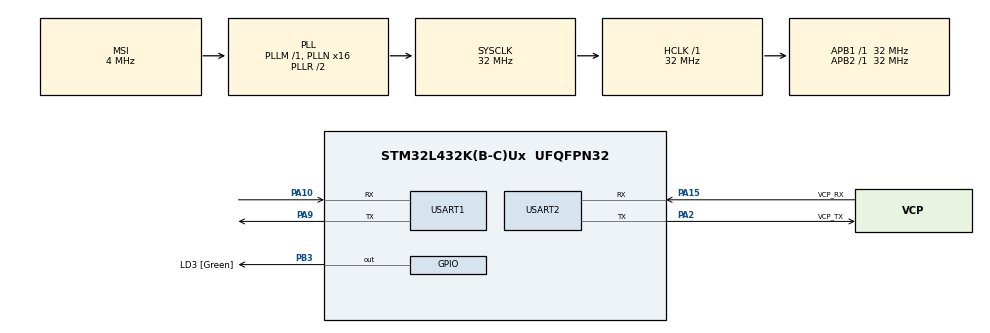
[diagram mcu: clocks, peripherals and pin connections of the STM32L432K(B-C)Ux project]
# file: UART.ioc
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Dma.Request0=USART1_RX
Dma.USART1_RX.0.Direction=DMA_PERIPH_TO_MEMORY
Dma.USART1_RX.0.Instance=DMA1_Channel5
Dma.USART1_RX.0.MemDataAlignment=DMA_MDATAALIGN_BYTE
Dma.USART1_RX.0.MemInc=DMA_MINC_ENABLE
Dma.USART1_RX.0.Mode=DMA_CIRCULAR
Dma.USART1_RX.0.PeriphDataAlignment=DMA_PDATAALIGN_BYTE
Dma.USART1_RX.0.PeriphInc=DMA_PINC_DISABLE
Dma.USART1_RX.0.Priority=DMA_PRIORITY_LOW
Mcu.Family=STM32L4
Mcu.Name=STM32L432K(B-C)Ux
Mcu.Package=UFQFPN32
NVIC.DMA1_Channel5_IRQn=true\:0\:0\:false\:false\:true\:false\:true
NVIC.PriorityGroup=NVIC_PRIORITYGROUP_4
NVIC.TIM6_DAC_IRQn=true\:0\:0\:false\:false\:true\:true\:true
NVIC.USART1_IRQn=true\:0\:0\:false\:false\:true\:true\:true
PA0.GPIO_Label=MCO [High speed clock in]
PA0.Mode=HSE-External-Clock-Source-for-LittleOrca
PA0.Signal=RCC_CK_IN
PA10.Mode=Asynchronous
PA10.Signal=USART1_RX
PA13\ (JTMS-SWDIO).GPIO_Label=SWDIO
PA13\ (JTMS-SWDIO).Mode=Serial_Wire
PA13\ (JTMS-SWDIO).Signal=SYS_JTMS-SWDIO
PA14\ (JTCK-SWCLK).GPIO_Label=SWCLK
PA14\ (JTCK-SWCLK).Mode=Serial_Wire
PA14\ (JTCK-SWCLK).Signal=SYS_JTCK-SWCLK
PA15\ (JTDI).GPIO_Label=VCP_RX
PA15\ (JTDI).Mode=Asynchronous
PA15\ (JTDI).Signal=USART2_RX
PA2.GPIO_Label=VCP_TX
PA2.Mode=Asynchronous
PA2.Signal=USART2_TX
PA9.Mode=Asynchronous
PA9.Signal=USART1_TX
PB3\ (JTDO-TRACESWO).GPIO_Label=LD3 [Green]
PB3\ (JTDO-TRACESWO).Signal=GPIO_Output
PC14-OSC32_IN\ (PC14).Mode=LSE-External-Oscillator
PC14-OSC32_IN\ (PC14).Signal=RCC_OSC32_IN
PC15-OSC32_OUT\ (PC15).Mode=LSE-External-Oscillator
PC15-OSC32_OUT\ (PC15).Signal=RCC_OSC32_OUT
ProjectManager.HeapSize=0x200
ProjectManager.StackSize=0x400
ProjectManager.TargetToolchain=STM32CubeIDE
RCC.AHBFreq_Value=32000000
RCC.APB1Freq_Value=32000000
RCC.APB1TimFreq_Value=32000000
RCC.APB2Freq_Value=32000000
RCC.APB2TimFreq_Value=32000000
RCC.CortexFreq_Value=32000000
RCC.HCLKFreq_Value=32000000
RCC.HSE_VALUE=8000000
RCC.HSI16_VALUE=16000000
RCC.HSI48_VALUE=48000000
RCC.HSI_VALUE=16000000
RCC.MSI_VALUE=4000000
RCC.PLLMUL=RCC_PLLMUL_4
RCC.PLLN=16
RCC.SYSCLKFreq_VALUE=32000000
RCC.SYSCLKSource=RCC_SYSCLKSOURCE_PLLCLK
RCC.VCOOutputFreq_Value=64000000
TIM6.Period=10000
TIM6.Prescaler=32
USART1.OverrunDisableParam=ADVFEATURE_OVERRUN_ENABLE
USART1.Parity=PARITY_NONE
USART1.VirtualMode-Asynchronous=VM_ASYNC
USART2.VirtualMode-Asynchronous=VM_ASYNC
VP_TIM6_VS_ClockSourceINT.Mode=Enable_Timer
board=NUCLEO-L432KC

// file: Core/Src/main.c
/* USER CODE BEGIN Header */
/**
  ******************************************************************************
  * @file           : main.c
  * @brief          : Main program body
  ******************************************************************************
  * @attention
  *
  * <h2><center>&copy; Copyright (c) 2020 STMicroelectronics.
  * All rights reserved.</center></h2>
  *
  * This software component is licensed by ST under BSD 3-Clause license,
  * the "License"; You may not use this file except in compliance with the
  * License. You may obtain a copy of the License at:
  *                        opensource.org/licenses/BSD-3-Clause
  *
  ******************************************************************************
  */
/* USER CODE END Header */
#include "main.h"

/* USER CODE BEGIN Includes */

#include <stdio.h>
#include <sys/_stdint.h>
#include <string.h>
#include <com.h>

/* USER CODE END Includes */

TIM_HandleTypeDef htim6;

UART_HandleTypeDef huart1;
UART_HandleTypeDef huart2;
DMA_HandleTypeDef hdma_usart1_rx;

/* USER CODE BEGIN PV */

//DMA buffer for UART
char RX_Buffer[16];

/* USER CODE END PV */

void SystemClock_Config(void);
static void MX_GPIO_Init(void);
static void MX_DMA_Init(void);
static void MX_USART2_UART_Init(void);
static void MX_USART1_UART_Init(void);
static void MX_TIM6_Init(void);

/* USER CODE BEGIN 0 */

//reroute printf to UART1
int _write(int file, char *ptr, int len)
{
	HAL_UART_Transmit(&huart1,  (uint8_t*) ptr, len, 10);
    return len;
}

/* USER CODE END 0 */

int main(void)
{

  /* MCU Configuration--------------------------------------------------------*/

  /* Reset of all peripherals, Initializes the Flash interface and the Systick. */
  HAL_Init();

  /* Configure the system clock */
  SystemClock_Config();

  /* Initialize all configured peripherals */
  MX_GPIO_Init();
  MX_DMA_Init();
  MX_USART2_UART_Init();
  MX_USART1_UART_Init();
  MX_TIM6_Init();
  /* USER CODE BEGIN 2 */

  HAL_TIM_Base_Start_IT(&htim6);

  /* USER CODE END 2 */

  /* Infinite loop */
  while (1)
  {

	  //everything is handled inside ISR

  }
}

void SystemClock_Config(void)
{
  RCC_OscInitTypeDef RCC_OscInitStruct = {0};
  RCC_ClkInitTypeDef RCC_ClkInitStruct = {0};
  RCC_PeriphCLKInitTypeDef PeriphClkInit = {0};

  /** Configure LSE Drive Capability
  */
  HAL_PWR_EnableBkUpAccess();
  __HAL_RCC_LSEDRIVE_CONFIG(RCC_LSEDRIVE_LOW);
  /** Initializes the RCC Oscillators according to the specified parameters
  * in the RCC_OscInitTypeDef structure.
  */
  RCC_OscInitStruct.OscillatorType = RCC_OSCILLATORTYPE_LSE|RCC_OSCILLATORTYPE_MSI;
  RCC_OscInitStruct.LSEState = RCC_LSE_ON;
  RCC_OscInitStruct.MSIState = RCC_MSI_ON;
  RCC_OscInitStruct.MSICalibrationValue = 0;
  RCC_OscInitStruct.MSIClockRange = RCC_MSIRANGE_6;
  RCC_OscInitStruct.PLL.PLLState = RCC_PLL_ON;
  RCC_OscInitStruct.PLL.PLLSource = RCC_PLLSOURCE_MSI;
  RCC_OscInitStruct.PLL.PLLM = 1;
  RCC_OscInitStruct.PLL.PLLN = 16;
  RCC_OscInitStruct.PLL.PLLP = RCC_PLLP_DIV7;
  RCC_OscInitStruct.PLL.PLLQ = RCC_PLLQ_DIV2;
  RCC_OscInitStruct.PLL.PLLR = RCC_PLLR_DIV2;
  if (HAL_RCC_OscConfig(&RCC_OscInitStruct) != HAL_OK)
  {
    Error_Handler();
  }
  /** Initializes the CPU, AHB and APB buses clocks
  */
  RCC_ClkInitStruct.ClockType = RCC_CLOCKTYPE_HCLK|RCC_CLOCKTYPE_SYSCLK
                              |RCC_CLOCKTYPE_PCLK1|RCC_CLOCKTYPE_PCLK2;
  RCC_ClkInitStruct.SYSCLKSource = RCC_SYSCLKSOURCE_PLLCLK;
  RCC_ClkInitStruct.AHBCLKDivider = RCC_SYSCLK_DIV1;
  RCC_ClkInitStruct.APB1CLKDivider = RCC_HCLK_DIV1;
  RCC_ClkInitStruct.APB2CLKDivider = RCC_HCLK_DIV1;

  if (HAL_RCC_ClockConfig(&RCC_ClkInitStruct, FLASH_LATENCY_1) != HAL_OK)
  {
    Error_Handler();
  }
  PeriphClkInit.PeriphClockSelection = RCC_PERIPHCLK_USART1|RCC_PERIPHCLK_USART2;
  PeriphClkInit.Usart1ClockSelection = RCC_USART1CLKSOURCE_PCLK2;
  PeriphClkInit.Usart2ClockSelection = RCC_USART2CLKSOURCE_PCLK1;
  if (HAL_RCCEx_PeriphCLKConfig(&PeriphClkInit) != HAL_OK)
  {
    Error_Handler();
  }
  /** Configure the main internal regulator output voltage
  */
  if (HAL_PWREx_ControlVoltageScaling(PWR_REGULATOR_VOLTAGE_SCALE1) != HAL_OK)
  {
    Error_Handler();
  }
  /** Enable MSI Auto calibration
  */
  HAL_RCCEx_EnableMSIPLLMode();
}

static void MX_TIM6_Init(void)
{

  TIM_MasterConfigTypeDef sMasterConfig = {0};

  htim6.Instance = TIM6;
  htim6.Init.Prescaler = 32;
  htim6.Init.CounterMode = TIM_COUNTERMODE_UP;
  htim6.Init.Period = 10000;
  htim6.Init.AutoReloadPreload = TIM_AUTORELOAD_PRELOAD_DISABLE;
  if (HAL_TIM_Base_Init(&htim6) != HAL_OK)
  {
    Error_Handler();
  }
  sMasterConfig.MasterOutputTrigger = TIM_TRGO_RESET;
  sMasterConfig.MasterSlaveMode = TIM_MASTERSLAVEMODE_DISABLE;
  if (HAL_TIMEx_MasterConfigSynchronization(&htim6, &sMasterConfig) != HAL_OK)
  {
    Error_Handler();
  }

}

static void MX_USART1_UART_Init(void)
{

  huart1.Instance = USART1;
  huart1.Init.BaudRate = 115200;
  huart1.Init.WordLength = UART_WORDLENGTH_8B;
  huart1.Init.StopBits = UART_STOPBITS_1;
  huart1.Init.Parity = UART_PARITY_NONE;
  huart1.Init.Mode = UART_MODE_TX_RX;
  huart1.Init.HwFlowCtl = UART_HWCONTROL_NONE;
  huart1.Init.OverSampling = UART_OVERSAMPLING_16;
  huart1.Init.OneBitSampling = UART_ONE_BIT_SAMPLE_DISABLE;
  huart1.AdvancedInit.AdvFeatureInit = UART_ADVFEATURE_NO_INIT;
  if (HAL_UART_Init(&huart1) != HAL_OK)
  {
    Error_Handler();
  }
  /* USER CODE BEGIN USART1_Init 2 */

  //enable DMA for USART1
  HAL_UART_Receive_DMA(&huart1, (uint8_t*)RX_Buffer, 16U);

  /* USER CODE END USART1_Init 2 */

}

static void MX_USART2_UART_Init(void)
{

  huart2.Instance = USART2;
  huart2.Init.BaudRate = 115200;
  huart2.Init.WordLength = UART_WORDLENGTH_8B;
  huart2.Init.StopBits = UART_STOPBITS_1;
  huart2.Init.Parity = UART_PARITY_NONE;
  huart2.Init.Mode = UART_MODE_TX_RX;
  huart2.Init.HwFlowCtl = UART_HWCONTROL_NONE;
  huart2.Init.OverSampling = UART_OVERSAMPLING_16;
  huart2.Init.OneBitSampling = UART_ONE_BIT_SAMPLE_DISABLE;
  huart2.AdvancedInit.AdvFeatureInit = UART_ADVFEATURE_NO_INIT;
  if (HAL_UART_Init(&huart2) != HAL_OK)
  {
    Error_Handler();
  }

}

static void MX_DMA_Init(void)
{

  /* DMA controller clock enable */
  __HAL_RCC_DMA1_CLK_ENABLE();

  /* DMA interrupt init */
  /* DMA1_Channel5_IRQn interrupt configuration */
  HAL_NVIC_SetPriority(DMA1_Channel5_IRQn, 0, 0);
  HAL_NVIC_EnableIRQ(DMA1_Channel5_IRQn);

}

static void MX_GPIO_Init(void)
{
  GPIO_InitTypeDef GPIO_InitStruct = {0};

  /* GPIO Ports Clock Enable */
  __HAL_RCC_GPIOC_CLK_ENABLE();
  __HAL_RCC_GPIOA_CLK_ENABLE();
  __HAL_RCC_GPIOB_CLK_ENABLE();

  /*Configure GPIO pin Output Level */
  HAL_GPIO_WritePin(LD3_GPIO_Port, LD3_Pin, GPIO_PIN_RESET);

  /*Configure GPIO pin : LD3_Pin */
  GPIO_InitStruct.Pin = LD3_Pin;
  GPIO_InitStruct.Mode = GPIO_MODE_OUTPUT_PP;
  GPIO_InitStruct.Pull = GPIO_NOPULL;
  GPIO_InitStruct.Speed = GPIO_SPEED_FREQ_LOW;
  HAL_GPIO_Init(LD3_GPIO_Port, &GPIO_InitStruct);

}

void Error_Handler(void)
{
}

/************************ (C) COPYRIGHT STMicroelectronics *****END OF FILE****/
